AUTOSAR XML (schema 00044)
package /E40_Platform_System_SystemPackage/Components
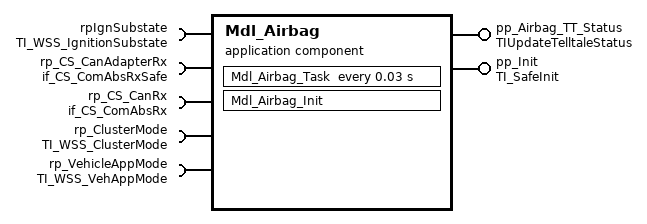
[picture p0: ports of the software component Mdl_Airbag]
  application sw component type Mdl_Airbag
    provide port pp_Airbag_TT_Status: nonqueued-sender-com-spec{data-element=CurrentTelltaleStatus, init-value=constant-reference=Mdl_AirbagCurrentTelltaleStatusValue0}, provided-interface=TIUpdateTelltaleStatus
    provide port pp_Init: server-com-spec{operation=Init, queue-length=1}, provided-interface=TI_SafeInit
    5 x require port:
      rpIgnSubstate: nonqueued-receiver-com-spec{data-element=IgnitionSubstate, init-value=constant-reference=Mdl_AirbagIgnitionSubstateValue0}, required-interface=TI_WSS_IgnitionSubstate
      rp_CS_CanAdapterRx: required-interface=if_CS_ComAbsRxSafe
        required-com-specs:
          RxCan_GetSignalValue
          RxCan_GetSignalValueU8Arr
          RxCan_SetSignalInitValue
          RxCan_SetSignalInitValueU8Arr
          RxCan_SignalClearJustRcvdStatus
          RxCan_SignalGetJustRcvdStatus
          RxCan_SignalInvalidProcessingControl
          RxCan_SignalMissingProcessingControl
          RxCan_SignalNRProcessingControl
      rp_CS_CanRx: required-interface=if_CS_ComAbsRx
        required-com-specs:
          RxCan_GetSignalValue
          RxCan_GetSignalValueU8Arr
          RxCan_SetSignalInitValue
          RxCan_SetSignalInitValueU8Arr
          RxCan_SignalClearJustRcvdStatus
          RxCan_SignalGetJustRcvdStatus
          RxCan_SignalInvalidProcessingControl
          RxCan_SignalMissingProcessingControl
          RxCan_SignalNRProcessingControl
      rp_ClusterMode: nonqueued-receiver-com-spec{data-element=WSSCurrentClusterMode, init-value=constant-reference=Mdl_AirbagWSSCurrentClusterModeValue0}, required-interface=TI_WSS_ClusterMode
      rp_VehicleAppMode: nonqueued-receiver-com-spec{data-element=WSSCurrentVehicleState, init-value=constant-reference=Mdl_AirbagWSSCurrentVehicleStateValue0}, required-interface=TI_WSS_VehAppMode
    behavior IB_Mdl_Airbag
      operation invoked event OIE_pp_Init_Mdl_Airbag_InitTrigByInit: start-on-event=Mdl_Airbag_Init, operation=pp_Init.Init
      timing event TEMdl_Airbag_Task: start-on-event=Mdl_Airbag_Task, period=0.03
      port-api-options:
        enable-take-address=false, indirect-api=false, port=pp_Airbag_TT_Status
        enable-take-address=false, indirect-api=false, port=pp_Init
        enable-take-address=false, indirect-api=false, port=rpIgnSubstate
        enable-take-address=false, indirect-api=false, port=rp_CS_CanAdapterRx
        enable-take-address=false, indirect-api=false, port=rp_CS_CanRx
        enable-take-address=false, indirect-api=false, port=rp_ClusterMode
        enable-take-address=false, indirect-api=false, port=rp_VehicleAppMode
      runnable Mdl_Airbag_Init: can-be-invoked-concurrently=true
      runnable Mdl_Airbag_Task: can-be-invoked-concurrently=true
        data-receive-point-by-arguments:
          access DRA_rp_ClusterMode_WSSCurrentClusterMode: accessed-variable=rp_ClusterMode.WSSCurrentClusterMode
          access DRA_rpIgnSubstate_IgnitionSubstate: accessed-variable=rpIgnSubstate.IgnitionSubstate
          access DRA_rp_VehicleAppMode_WSSCurrentVehicleState: accessed-variable=rp_VehicleAppMode.WSSCurrentVehicleState
        data-send-points:
          access DWA_pp_Airbag_TT_Status_CurrentTelltaleStatus: accessed-variable=pp_Airbag_TT_Status.CurrentTelltaleStatus
        18 x sync call:
          OA_rp_CS_CanAdapterRx_RxCan_SignalInvalidProcessingControl: operation=rp_CS_CanAdapterRx.RxCan_SignalInvalidProcessingControl
          OA_rp_CS_CanAdapterRx_RxCan_SignalMissingProcessingControl: operation=rp_CS_CanAdapterRx.RxCan_SignalMissingProcessingControl
          OA_rp_CS_CanAdapterRx_RxCan_SignalNRProcessingControl: operation=rp_CS_CanAdapterRx.RxCan_SignalNRProcessingControl
          OA_rp_CS_CanAdapterRx_RxCan_SetSignalInitValue: operation=rp_CS_CanAdapterRx.RxCan_SetSignalInitValue
          OA_rp_CS_CanRx_RxCan_GetSignalValueU8Arr: operation=rp_CS_CanRx.RxCan_GetSignalValueU8Arr
          OA_rp_CS_CanRx_RxCan_SetSignalInitValue: operation=rp_CS_CanRx.RxCan_SetSignalInitValue
          OA_rp_CS_CanRx_RxCan_SetSignalInitValueU8Arr: operation=rp_CS_CanRx.RxCan_SetSignalInitValueU8Arr
          OA_rp_CS_CanRx_RxCan_SignalInvalidProcessingControl: operation=rp_CS_CanRx.RxCan_SignalInvalidProcessingControl
          OA_rp_CS_CanRx_RxCan_SignalMissingProcessingControl: operation=rp_CS_CanRx.RxCan_SignalMissingProcessingControl
          OA_rp_CS_CanRx_RxCan_SignalNRProcessingControl: operation=rp_CS_CanRx.RxCan_SignalNRProcessingControl
          OA_rp_CS_CanRx_RxCan_SignalGetJustRcvdStatus: operation=rp_CS_CanRx.RxCan_SignalGetJustRcvdStatus
          OA_rp_CS_CanRx_RxCan_SignalClearJustRcvdStatus: operation=rp_CS_CanRx.RxCan_SignalClearJustRcvdStatus
          OA_rp_CS_CanRx_RxCan_GetSignalValue: operation=rp_CS_CanRx.RxCan_GetSignalValue
          OA_rp_CS_CanAdapterRx_RxCan_GetSignalValueU8Arr: operation=rp_CS_CanAdapterRx.RxCan_GetSignalValueU8Arr
          OA_rp_CS_CanAdapterRx_RxCan_SetSignalInitValueU8Arr: operation=rp_CS_CanAdapterRx.RxCan_SetSignalInitValueU8Arr
          OA_rp_CS_CanAdapterRx_RxCan_SignalGetJustRcvdStatus: operation=rp_CS_CanAdapterRx.RxCan_SignalGetJustRcvdStatus
          OA_rp_CS_CanAdapterRx_RxCan_SignalClearJustRcvdStatus: operation=rp_CS_CanAdapterRx.RxCan_SignalClearJustRcvdStatus
          OA_rp_CS_CanAdapterRx_RxCan_GetSignalValue: operation=rp_CS_CanAdapterRx.RxCan_GetSignalValue
  swc implementation IMPL_Mdl_Airbag: behavior=IB_Mdl_Airbag
